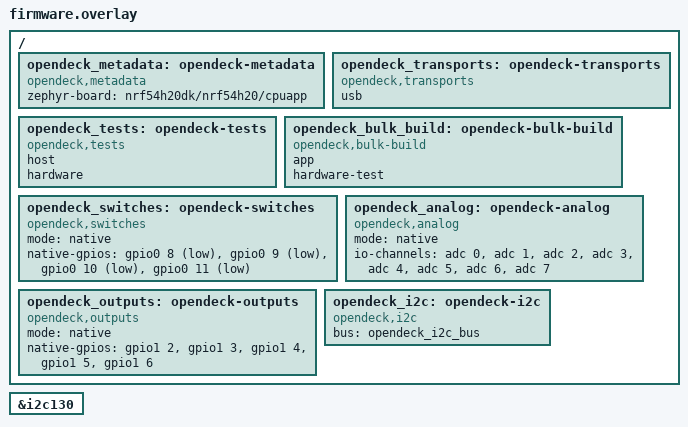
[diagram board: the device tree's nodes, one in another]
/ {
    opendeck_metadata: opendeck-metadata {
        compatible = "opendeck,metadata";
        zephyr-board = "nrf54h20dk/nrf54h20/cpuapp";
    };

    opendeck_transports: opendeck-transports {
        compatible = "opendeck,transports";
        usb;
    };

    opendeck_tests: opendeck-tests {
        compatible = "opendeck,tests";
        host;
        hardware;
    };

    opendeck_bulk_build: opendeck-bulk-build {
        compatible = "opendeck,bulk-build";
        app;
        hardware-test;
    };

    opendeck_switches: opendeck-switches {
        compatible = "opendeck,switches";
        mode = "native";
        native-gpios =
            <&gpio0 8 (GPIO_PULL_UP | GPIO_ACTIVE_LOW)>,
            <&gpio0 9 (GPIO_PULL_UP | GPIO_ACTIVE_LOW)>,
            <&gpio0 10 (GPIO_PULL_UP | GPIO_ACTIVE_LOW)>,
            <&gpio0 11 (GPIO_PULL_UP | GPIO_ACTIVE_LOW)>;
    };

    opendeck_analog: opendeck-analog {
        compatible = "opendeck,analog";
        mode = "native";
        io-channels =
            <&adc 0>,
            <&adc 1>,
            <&adc 2>,
            <&adc 3>,
            <&adc 4>,
            <&adc 5>,
            <&adc 6>,
            <&adc 7>;
    };

    opendeck_outputs: opendeck-outputs {
        compatible = "opendeck,outputs";
        mode = "native";
        native-gpios =
            <&gpio1 2 GPIO_ACTIVE_HIGH>,
            <&gpio1 3 GPIO_ACTIVE_HIGH>,
            <&gpio1 4 GPIO_ACTIVE_HIGH>,
            <&gpio1 5 GPIO_ACTIVE_HIGH>,
            <&gpio1 6 GPIO_ACTIVE_HIGH>;
    };

    opendeck_i2c: opendeck-i2c {
        compatible = "opendeck,i2c";
        bus = <&opendeck_i2c_bus>;
    };
};

opendeck_i2c_bus: &i2c130 {};

&i2c130 {
    status = "okay";
};
